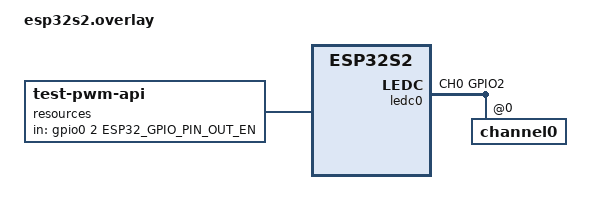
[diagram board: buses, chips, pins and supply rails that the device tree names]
/*
 * SPDX-License-Identifier: Apache-2.0
 *
 * Copyright (c) 2024 Espressif Systems (Shanghai) Co., Ltd.
 */

#include <zephyr/dt-bindings/pwm/pwm.h>
#include <zephyr/dt-bindings/gpio/gpio.h>
#include <zephyr/dt-bindings/gpio/espressif-esp32-gpio.h>

/ {
	aliases {
		pwm-0 = &ledc0;
	};

	resources {
		compatible = "test-pwm-api";
		in-gpios = <&gpio0 2 ESP32_GPIO_PIN_OUT_EN>;
	};
};

&pinctrl {
	ledc0_default: ledc0_default {
		group1 {
			pinmux = <LEDC_CH0_GPIO2>;
			input-enable;
		};
	};
};

&ledc0 {
	pinctrl-0 = <&ledc0_default>;
	pinctrl-names = "default";
	status = "okay";
	#address-cells = <1>;
	#size-cells = <0>;
	channel0@0 {
		reg = <0x0>;
		timer = <0>;
	};
};
